# STM32WB1Mxx register map
File version: 1.0
Registers are 32-bit, read-write, reset 0x0 unless marked. A register's access mark holds for its fields unless they carry their own. Offsets are from the block's base; [hi:lo] are bit positions; lines under a group give offsets from that group; {n}, {i} and the like mark numbered series.

## ADC1 — Analog to Digital Converter
Base 0x40012400
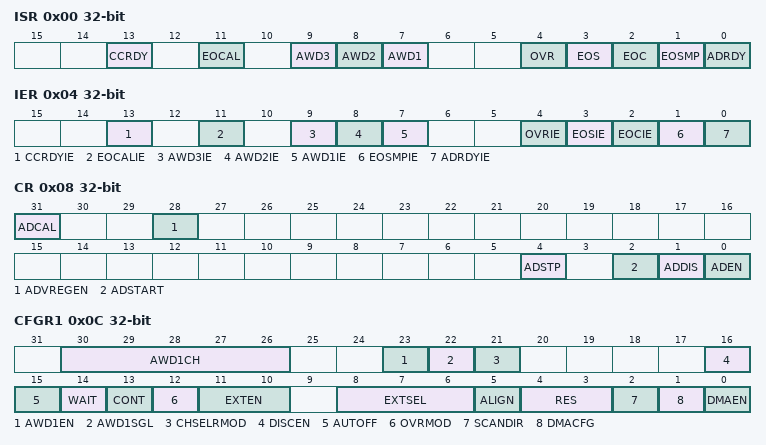
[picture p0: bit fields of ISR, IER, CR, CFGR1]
0x00 ISR — ADC interrupt and status register
  [13] CCRDY — ADC channel configuration ready flag
  [11] EOCAL — ADC end of calibration flag
  [9] AWD3 — ADC analog watchdog 3 flag
  [8] AWD2 — ADC analog watchdog 2 flag
  [7] AWD1 — ADC analog watchdog 1 flag
  [4] OVR — ADC group regular overrun flag
  [3] EOS — ADC group regular end of sequence conversions flag
  [2] EOC — ADC group regular end of unitary conversion flag
  [1] EOSMP — ADC group regular end of sampling flag
  [0] ADRDY — ADC ready flag
0x04 IER — ADC interrupt enable register
  [13] CCRDYIE — ADC channel configuration ready interrupt
  [11] EOCALIE — ADC end of calibration interrupt
  [9] AWD3IE — ADC analog watchdog 3 interrupt
  [8] AWD2IE — ADC analog watchdog 2 interrupt
  [7] AWD1IE — ADC analog watchdog 1 interrupt
  [4] OVRIE — ADC group regular overrun interrupt
  [3] EOSIE — ADC group regular end of sequence conversions interrupt
  [2] EOCIE — ADC group regular end of unitary conversion interrupt
  [1] EOSMPIE — ADC group regular end of sampling interrupt
  [0] ADRDYIE — ADC ready interrupt
0x08 CR — ADC control register
  [31] ADCAL — ADC calibration
  [28] ADVREGEN — ADC voltage regulator enable
  [4] ADSTP — ADC group regular conversion stop
  [2] ADSTART — ADC group regular conversion start
  [1] ADDIS — ADC disable
  [0] ADEN — ADC enable
0x0C CFGR1 — ADC configuration register 1
  [30:26] AWD1CH — ADC analog watchdog 1 monitored channel selection
  [23] AWD1EN — ADC analog watchdog 1 enable on scope ADC group regular
  [22] AWD1SGL — ADC analog watchdog 1 monitoring a single channel or all channels
  [21] CHSELRMOD — ADC group regular sequencer mode
    0=FIXED (Sequencer configured to fully configurable: sequencer length and each rank affectation to a channel are configurable. Refer to description of function @ref LL_ADC_REG_SetSequencerLength().); 1=CONFIGURABLE (Sequencer configured to not fully configurable: sequencer length and each rank affectation to a channel are fixed by channel HW number. Refer to description of function @ref LL_ADC_REG_SetSequencerChannels().)
  [16] DISCEN — ADC group regular sequencer discontinuous mode
  [15] AUTOFF — ADC low power auto power off
  [14] WAIT — ADC low power auto wait
  [13] CONT — ADC group regular continuous conversion mode
  [12] OVRMOD — ADC group regular overrun configuration
  [11:10] EXTEN — ADC group regular external trigger polarity
  [8:6] EXTSEL — ADC group regular external trigger source
  [5] ALIGN — ADC data alignment
  [4:3] RES — ADC data resolution
  [2] SCANDIR — ADC group regular sequencer scan direction
    0=FORWARD (On this STM32 series, parameter relevant only is sequencer set to mode not fully configurable, refer to function @ref LL_ADC_REG_SetSequencerConfigurable(). ADC group regular sequencer scan direction forward: from lowest channel number to highest channel number (scan of all ranks, ADC conversion of ranks with channels enabled in sequencer). On some other STM32 families, this setting is not available and the default scan direction is forward.); 1=BACKWARD (On this STM32 series, parameter relevant only is sequencer set to mode not fully configurable, refer to function @ref LL_ADC_REG_SetSequencerConfigurable(). ADC group regular sequencer scan direction backward: from highest channel number to lowest channel number (scan of all ranks, ADC conversion of ranks with channels enabled in sequencer))
  [1] DMACFG — ADC DMA transfer configuration
  [0] DMAEN — ADC DMA transfer enable
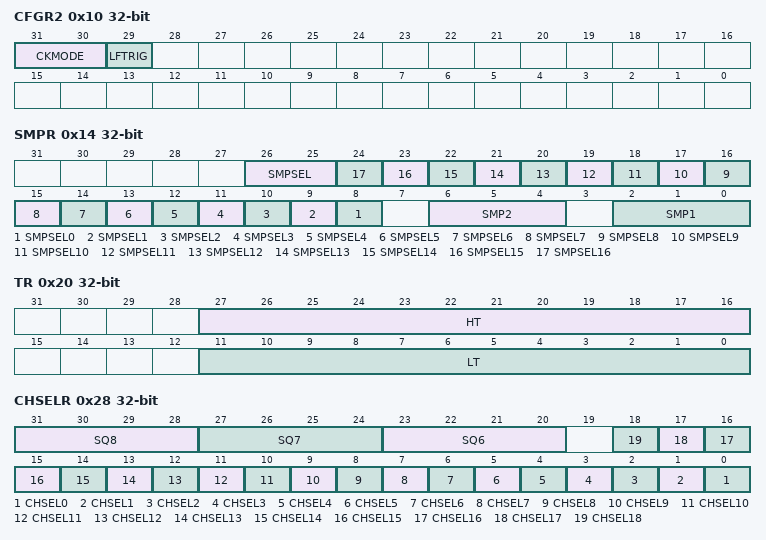
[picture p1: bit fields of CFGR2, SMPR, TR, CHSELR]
0x10 CFGR2 — ADC configuration register 2
  [31:30] CKMODE — ADC clock source and prescaler (prescaler only for clock source synchronous)
    2=SYNC_PCLK_DIV4 (ADC synchronous clock derived from AHB clock with prescaler division by 4); 1=SYNC_PCLK_DIV2 (ADC synchronous clock derived from AHB clock with prescaler division by 2); 3=SYNC_PCLK_DIV1 (ADC synchronous clock derived from AHB clock without prescaler); 0=ASYNC (ADC asynchronous clock. Asynchronous clock prescaler can be configured using function @ref LL_ADC_SetCommonClock().)
  [29] LFTRIG — ADC low frequency trigger mode
    0=HIGH (ADC trigger frequency mode set to high frequency. Note: ADC trigger frequency mode must be set to low frequency when a duration is exceeded before ADC conversion start trigger event (between ADC enable and ADC conversion start trigger event or between two ADC conversion start trigger event). Duration value: Refer to device datasheet, parameter "tIdle".); 1=LOW (ADC trigger frequency mode set to low frequency. Note: ADC trigger frequency mode must be set to low frequency when a duration is exceeded before ADC conversion start trigger event (between ADC enable and ADC conversion start trigger event or between two ADC conversion start trigger event). Duration value: Refer to device datasheet, parameter "tIdle".)
0x14 SMPR — ADC sampling time register
  [26:25] SMPSEL — ADC all channels sampling time selection
  [n+8] SMPSEL{n} (n=0..16) — ADC channel {n} sampling time selection
  [6:4] SMP2 — ADC group of channels sampling time 2
  [2:0] SMP1 — ADC group of channels sampling time 1
0x20 TR — ADC analog watchdog 1 threshold register
  [27:16] HT — ADC Analog watchdog 1 threshold high
  [11:0] LT — ADC analog watchdog 1 threshold low
0x28 CHSELR — ADC group regular sequencer register
  [31:28] SQ8 — ADC group regular sequencer rank 8, available when ADC_CFGR1_CHSELRMOD is set
  [27:24] SQ7 — ADC group regular sequencer rank 7, available when ADC_CFGR1_CHSELRMOD is set
  [23:20] SQ6 — ADC group regular sequencer rank 6, available when ADC_CFGR1_CHSELRMOD is set
  [n] CHSEL{n} (n=0..18) — ADC group regular sequencer channel {n}, available when ADC_CFGR1_CHSELRMOD is reset
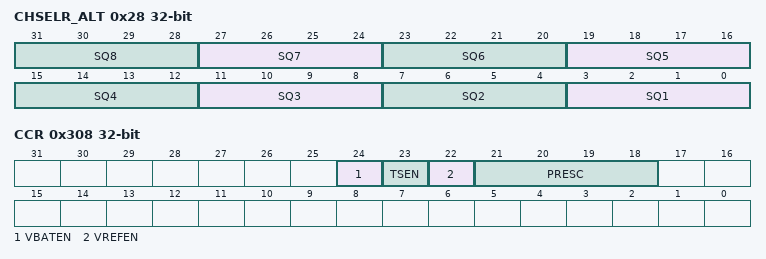
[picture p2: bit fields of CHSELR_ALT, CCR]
0x28 CHSELR_ALT (alternate view of CHSELR) — ADC group regular sequencer register
  [4n-1:4n-4] SQ{n} (n=1..8) — ADC group regular sequencer rank {n}, available when ADC_CFGR1_CHSELRMOD is set
0x40 DR — ADC group regular data register
  [15:0] DATA — ADC group regular conversion data
0xB4 CALFACT — ADC Calibration factor register
  [6:0] CALFACT — ADC calibration factor in single-ended mode
0x308 CCR — ADC common configuration register
  [24] VBATEN — ADC internal path to battery voltage enable
  [23] TSEN — ADC internal path to temperature sensor enable
  [22] VREFEN — ADC internal path to VrefInt enable
  [21:18] PRESC — ADC common clock prescaler, only for clock source asynchronous
